# RS1xxxx register map
Vendor: Silicon Lab Inc.; Series: ARMCM4; File version: 1.2
CPU: CM4 r1p0, little endian, MPU, FPU, 6 interrupt priority bits
Registers are 32-bit, read-write, reset 0x0 unless marked. A register's access mark holds for its fields unless they carry their own. Offsets are from the block's base; [hi:lo] are bit positions; 'fields as' and 'values as' point back to an identical list.

## High_Power_Domain — The use of this is to store some information in ULP over wake-ups to reduce wake-up time
Base 0x24048400
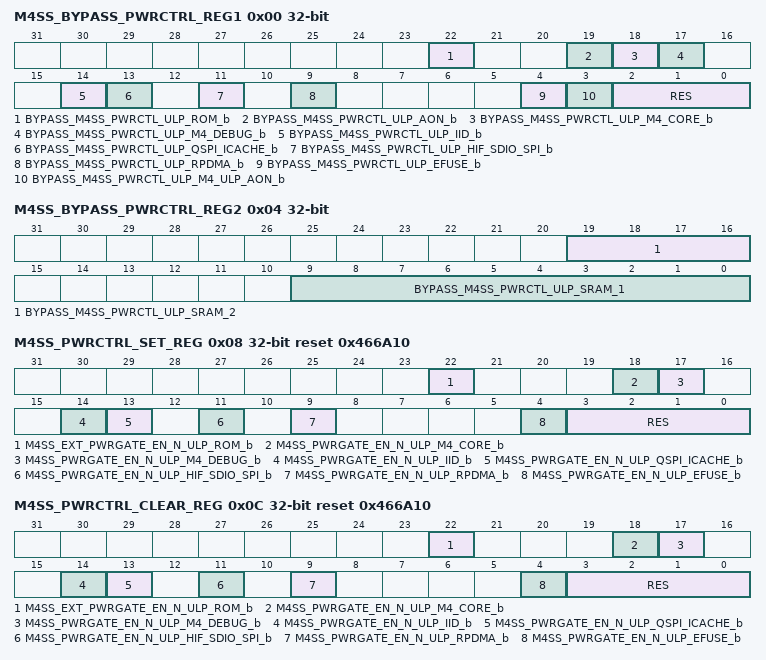
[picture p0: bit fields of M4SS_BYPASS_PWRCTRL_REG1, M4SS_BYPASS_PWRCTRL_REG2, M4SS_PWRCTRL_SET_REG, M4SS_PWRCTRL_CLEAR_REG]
0x00 M4SS_BYPASS_PWRCTRL_REG1 — M4ss bypass power control register 1
  [22] BYPASS_M4SS_PWRCTL_ULP_ROM_b — Enables software based control of isolation and reset for M4ss ROM
  [19] BYPASS_M4SS_PWRCTL_ULP_AON_b — Enables software based control of isolation and reset for ULP AON
  [18] BYPASS_M4SS_PWRCTL_ULP_M4_CORE_b — Enables software based control of isolation and reset for M4ss CORE
  [17] BYPASS_M4SS_PWRCTL_ULP_M4_DEBUG_b — Enables software based control of isolation and reset for M4ss DEBUG
  [14] BYPASS_M4SS_PWRCTL_ULP_IID_b — Enables software based control of isolation and reset for ULP IID
  [13] BYPASS_M4SS_PWRCTL_ULP_QSPI_ICACHE_b — Enables software based control of isolation and reset for ULP quad SPI and ICACHE
  [11] BYPASS_M4SS_PWRCTL_ULP_HIF_SDIO_SPI_b — Enables software based control of isolation and reset for HIF SDIO SPI
  [9] BYPASS_M4SS_PWRCTL_ULP_RPDMA_b — Enables software based control of isolation and reset for RPDMA
  [4] BYPASS_M4SS_PWRCTL_ULP_EFUSE_b — Enables software based control of isolation and reset for ULP EFUSE
  [3] BYPASS_M4SS_PWRCTL_ULP_M4_ULP_AON_b — Enables software based control of isolation and reset for ULP AON M4ss
  [2:0] RES ro — reserved1
0x04 M4SS_BYPASS_PWRCTRL_REG2 — M4SS bypass power control register 2
  [19:16] BYPASS_M4SS_PWRCTL_ULP_SRAM_2 — Enables software based control of isolation and reset for M4ss SRAM 2
  [9:0] BYPASS_M4SS_PWRCTL_ULP_SRAM_1 — Enables software based control of isolation and reset for M4ss SRAM 1
0x08 M4SS_PWRCTRL_SET_REG reset 0x466A10 — M4SS power control set register
  [22] M4SS_EXT_PWRGATE_EN_N_ULP_ROM_b — External power gate enable signal for ROM
  [18] M4SS_PWRGATE_EN_N_ULP_M4_CORE_b — Power Gate control for M4 CORE
  [17] M4SS_PWRGATE_EN_N_ULP_M4_DEBUG_b — Power Gate control for M4 DEBUG
  [14] M4SS_PWRGATE_EN_N_ULP_IID_b — Power Gate control for IID Block.If set, powered ON Clearing this bit has no effect
  [13] M4SS_PWRGATE_EN_N_ULP_QSPI_ICACHE_b — Power Gate control for QSPI and ICACHE
  [11] M4SS_PWRGATE_EN_N_ULP_HIF_SDIO_SPI_b — Power Gate control for HIF SDIO SPI
  [9] M4SS_PWRGATE_EN_N_ULP_RPDMA_b — Power Gate control for RPDMA
  [4] M4SS_PWRGATE_EN_N_ULP_EFUSE_b — Power Gate control for EFUSE
  [3:0] RES ro — reserved1
0x0C M4SS_PWRCTRL_CLEAR_REG reset 0x466A10 — M4SS power control clear register
  fields as M4SS_PWRCTRL_SET_REG
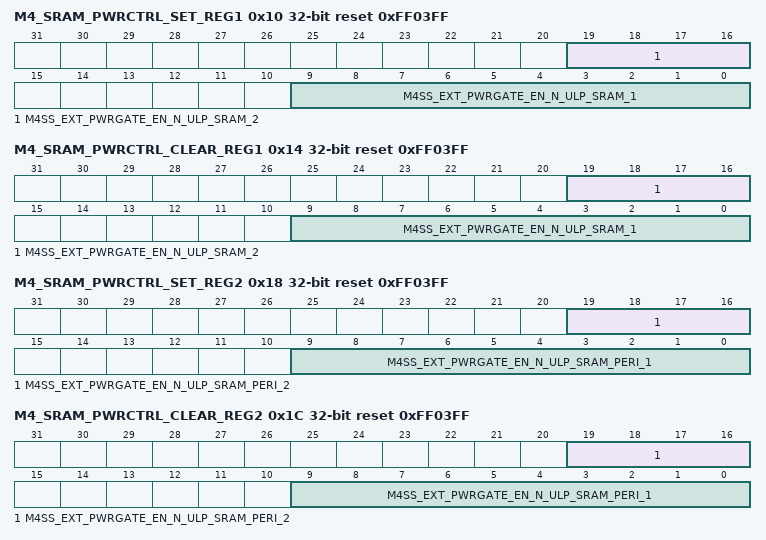
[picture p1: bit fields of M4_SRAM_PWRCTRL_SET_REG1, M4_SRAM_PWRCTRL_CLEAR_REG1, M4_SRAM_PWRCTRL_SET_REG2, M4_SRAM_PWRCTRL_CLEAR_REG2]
0x10 M4_SRAM_PWRCTRL_SET_REG1 reset 0xFF03FF — M4SS power control set register 1
  [19:16] M4SS_EXT_PWRGATE_EN_N_ULP_SRAM_2 — Functional Control signal for TASS SRAM shared with M4SS
  [9:0] M4SS_EXT_PWRGATE_EN_N_ULP_SRAM_1 — Functional Control signal for M4SS SRAM
0x14 M4_SRAM_PWRCTRL_CLEAR_REG1 reset 0xFF03FF — M4SS power control clear register 1
  fields as M4_SRAM_PWRCTRL_SET_REG1
0x18 M4_SRAM_PWRCTRL_SET_REG2 reset 0xFF03FF — M4SS power control set register 2
  [19:16] M4SS_EXT_PWRGATE_EN_N_ULP_SRAM_PERI_2 — Functional Control signal for TASS SRAM Dual Rail pins shared with M4SS
  [9:0] M4SS_EXT_PWRGATE_EN_N_ULP_SRAM_PERI_1 — Functional Control signal for M4SS SRAM Dual Rail pins
0x1C M4_SRAM_PWRCTRL_CLEAR_REG2 reset 0xFF03FF — M4SS power control clear register 2
  fields as M4_SRAM_PWRCTRL_SET_REG2
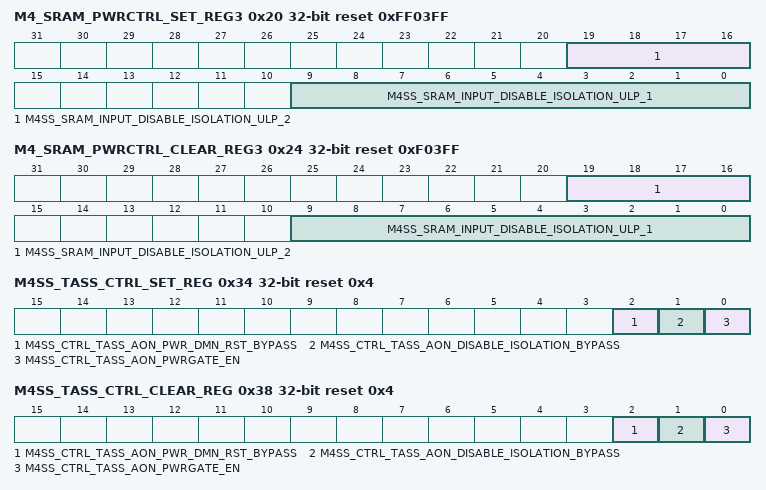
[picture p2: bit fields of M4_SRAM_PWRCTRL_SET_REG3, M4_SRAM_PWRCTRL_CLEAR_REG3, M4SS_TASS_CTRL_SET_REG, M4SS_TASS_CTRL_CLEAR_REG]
0x20 M4_SRAM_PWRCTRL_SET_REG3 reset 0xFF03FF — M4SS power control set register 3
  [19:16] M4SS_SRAM_INPUT_DISABLE_ISOLATION_ULP_2 — Input isolation control for TASS SRAM shared with M4SS
  [9:0] M4SS_SRAM_INPUT_DISABLE_ISOLATION_ULP_1 — Input isolation control for M4SS SRAM
0x24 M4_SRAM_PWRCTRL_CLEAR_REG3 reset 0xF03FF — M4SS power control clear register 3
  fields as M4_SRAM_PWRCTRL_SET_REG3
0x28 M4_SRAM_PWRCTRL_SET_REG4 — M4SS power control set register 4
  [23:0] M4SS_SRAM_DS_1 — Deep-Sleep control for M4SS SRAM
0x2C M4_SRAM_PWRCTRL_CLEAR_REG4 — M4SS power control clear register 4
  [23:0] M4SS_SRAM_DS_1 — Deep-Sleep control for M4SS SRAM
0x34 M4SS_TASS_CTRL_SET_REG reset 0x4 — M4SS_TASS control set register
  [2] M4SS_CTRL_TASS_AON_PWR_DMN_RST_BYPASS — M4SS controlling Power supply for TASS AON domains reset pin in bypass mode
  [1] M4SS_CTRL_TASS_AON_DISABLE_ISOLATION_BYPASS — M4SS controlling Power supply for TASS AON domains isolation enable in bypass mode
  [0] M4SS_CTRL_TASS_AON_PWRGATE_EN — M4SS controlling Power supply for TASS AON domain
0x38 M4SS_TASS_CTRL_CLEAR_REG reset 0x4 — M4SS_TASS control CLEAR register
  fields as M4SS_TASS_CTRL_SET_REG
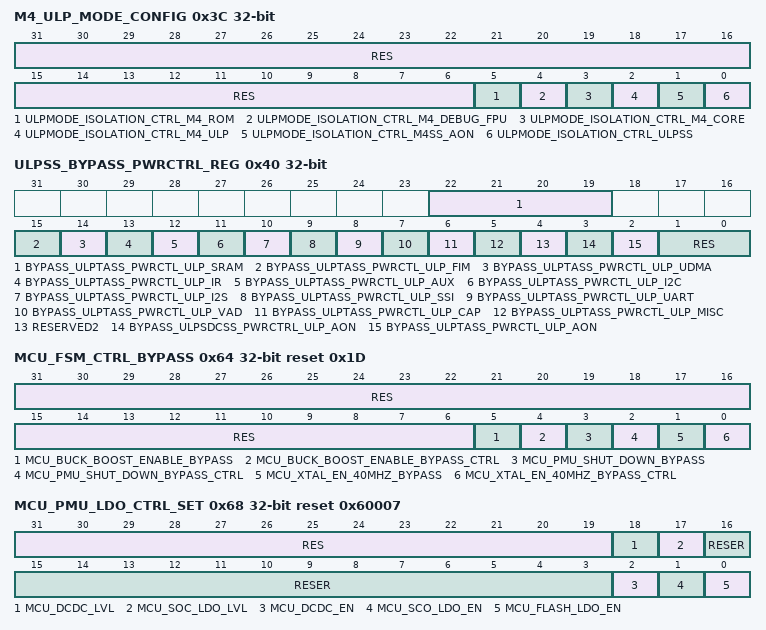
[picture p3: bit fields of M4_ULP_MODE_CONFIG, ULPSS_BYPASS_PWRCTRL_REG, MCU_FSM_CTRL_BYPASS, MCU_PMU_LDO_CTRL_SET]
0x3C M4_ULP_MODE_CONFIG
  [31:6] RES — reserved1
  [5] ULPMODE_ISOLATION_CTRL_M4_ROM — Isolation Control for ULP-Mode non-functional paths for ROM
  [4] ULPMODE_ISOLATION_CTRL_M4_DEBUG_FPU — Isolation Control for ULP-Mode non-functional paths for M4_DEBUG
  [3] ULPMODE_ISOLATION_CTRL_M4_CORE — Isolation Control for ULP-Mode non-functional paths for M4_CORE
  [2] ULPMODE_ISOLATION_CTRL_M4_ULP — Isolation Control for ULP-Mode non-functional paths for M4ULP_AON
  [1] ULPMODE_ISOLATION_CTRL_M4SS_AON — Isolation Control for ULP-Mode non-functional paths for M4SS-AON
  [0] ULPMODE_ISOLATION_CTRL_ULPSS — Isolation Control for ULP-Mode non-functional paths for ULPSS
0x40 ULPSS_BYPASS_PWRCTRL_REG — ULPSS bypass power control register
  [22:19] BYPASS_ULPTASS_PWRCTL_ULP_SRAM — Enables software based control of output isolation for ULPTASS SRAM
  [15] BYPASS_ULPTASS_PWRCTL_ULP_FIM — Enables software based control of output isolation for ULP FIM
  [14] BYPASS_ULPTASS_PWRCTL_ULP_UDMA — Enables software based control of output isolation for ULP UDMA
  [13] BYPASS_ULPTASS_PWRCTL_ULP_IR — Enables software based control of output isolation for ULP IR
  [12] BYPASS_ULPTASS_PWRCTL_ULP_AUX — Enables software based control of output isolation for ULP AUX
  [11] BYPASS_ULPTASS_PWRCTL_ULP_I2C — Enables software based control of output isolation for ULP I2C
  [10] BYPASS_ULPTASS_PWRCTL_ULP_I2S — Enables software based control of output isolation for ULP I2S
  [9] BYPASS_ULPTASS_PWRCTL_ULP_SSI — Enables software based control of output isolation for ULP SSI
  [8] BYPASS_ULPTASS_PWRCTL_ULP_UART — Enables software based control of output isolation for ULP UART
  [7] BYPASS_ULPTASS_PWRCTL_ULP_VAD — Enables software based control of output isolation for ULP VAD
  [6] BYPASS_ULPTASS_PWRCTL_ULP_CAP — Enables software based control of output isolation for ULP CAP
  [5] BYPASS_ULPTASS_PWRCTL_ULP_MISC — Enables software based control of output isolation for ULP MISC
  [4] RESERVED2 — reser
  [3] BYPASS_ULPSDCSS_PWRCTRL_ULP_AON — Enables software based control of output isolation for ULPSDCSS AON
  [2] BYPASS_ULPTASS_PWRCTL_ULP_AON — Enables software based control of output isolation for ULPTASS AON
  [1:0] RES — reserved1
0x64 MCU_FSM_CTRL_BYPASS reset 0x1D — MCU FSM control bypass register
  [31:6] RES — reserved1
  [5] MCU_BUCK_BOOST_ENABLE_BYPASS — Value for MCU BuckBoost Enable in bypass mode
  [4] MCU_BUCK_BOOST_ENABLE_BYPASS_CTRL — Enable software control for buck boost enable
  [3] MCU_PMU_SHUT_DOWN_BYPASS — Value of pmu shutdown in bypass mode
  [2] MCU_PMU_SHUT_DOWN_BYPASS_CTRL — Enable bypass mode to Control pmu shut down
  [1] MCU_XTAL_EN_40MHZ_BYPASS — Value of Xtal Enable in bypass mode
  [0] MCU_XTAL_EN_40MHZ_BYPASS_CTRL — Xtal 40mhz enable bypass from MCU
0x68 MCU_PMU_LDO_CTRL_SET reset 0x60007 — MCU PMU LD0 control set register
  [31:19] RES — reserved1
  [18] MCU_DCDC_LVL — PMU DCDC High and Low Voltage selection
  [17] MCU_SOC_LDO_LVL — PMU SOC LDO High and Low Voltage selection
  [16:3] RESER — reserved1
  [2] MCU_DCDC_EN — Enable PMU DCDC from M4SS
  [1] MCU_SCO_LDO_EN — Enable SoC LDO from M4SS
  [0] MCU_FLASH_LDO_EN — Enable Flash LDO from M4SS
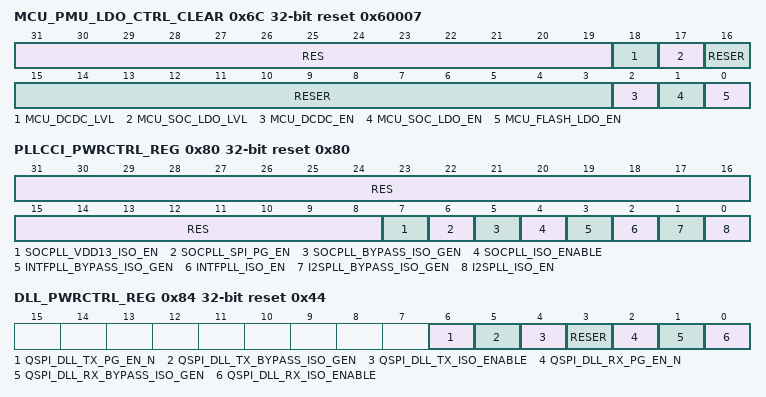
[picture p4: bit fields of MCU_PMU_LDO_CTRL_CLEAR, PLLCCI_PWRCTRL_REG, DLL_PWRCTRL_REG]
0x6C MCU_PMU_LDO_CTRL_CLEAR reset 0x60007 — MCU PMU LD0 control clear register
  [31:19] RES — reserved1
  [18] MCU_DCDC_LVL — PMU DCDC High and Low Voltage selection
  [17] MCU_SOC_LDO_LVL — PMU SOC LDO High and Low Voltage selection
  [16:3] RESER — reserved1
  [2] MCU_DCDC_EN — Enable PMU DCDC from M4SS
  [1] MCU_SOC_LDO_EN — Enable SoC LDO from M4SS
  [0] MCU_FLASH_LDO_EN — Enable Flash LDO from M4SS
0x80 PLLCCI_PWRCTRL_REG reset 0x80 — PLL CCI power control register
  [31:8] RES — reserved1
  [7] SOCPLL_VDD13_ISO_EN — SOCPLL MACRO POC Control
  [6] SOCPLL_SPI_PG_EN — SOCPLL SPI Power Control
  [5] SOCPLL_BYPASS_ISO_GEN — Isolation value
  [4] SOCPLL_ISO_ENABLE — Enables software based control of isolation and reset for SOCPLL
  [3] INTFPLL_BYPASS_ISO_GEN — Isolation value
  [2] INTFPLL_ISO_EN — Enables software based control of isolation and reset for INTF PLL
  [1] I2SPLL_BYPASS_ISO_GEN — Isolation value
  [0] I2SPLL_ISO_EN — Enables software based control of isolation and reset for I2SPLL
0x84 DLL_PWRCTRL_REG reset 0x44 — DLL power control register
  [6] QSPI_DLL_TX_PG_EN_N — QPSI DLL TX Power Control
  [5] QSPI_DLL_TX_BYPASS_ISO_GEN — Isolation value
  [4] QSPI_DLL_TX_ISO_ENABLE — Enables software based control of isolation and reset for QSPI_DLL_TX
  [3] RESER — reserved1
  [2] QSPI_DLL_RX_PG_EN_N — QPSI DLL RX Power Control
  [1] QSPI_DLL_RX_BYPASS_ISO_GEN — Isolation value
  [0] QSPI_DLL_RX_ISO_ENABLE — Enables software based control of isolation and reset for QSPI_DLL_TX
